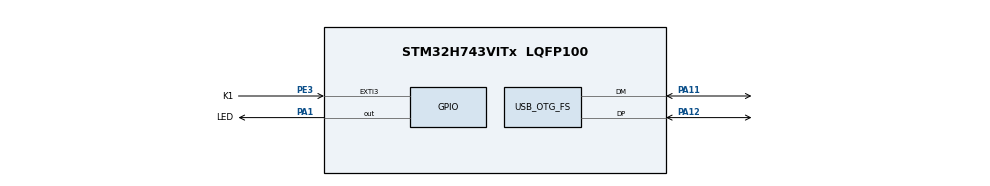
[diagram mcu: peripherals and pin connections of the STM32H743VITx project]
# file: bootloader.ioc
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CORTEX_M7.AccessPermission_S-Cortex_Memory_Protection_Unit_Region1_Settings_S=MPU_REGION_FULL_ACCESS
CORTEX_M7.BaseAddress_S-Cortex_Memory_Protection_Unit_Region1_Settings_S=0x20000000
CORTEX_M7.CPU_DCache=Enabled
CORTEX_M7.CPU_ICache=Enabled
CORTEX_M7.Enable_S-Cortex_Memory_Protection_Unit_Region1_Settings_S=MPU_REGION_ENABLE
CORTEX_M7.IsBufferable_S-Cortex_Memory_Protection_Unit_Region1_Settings_S=MPU_ACCESS_BUFFERABLE
CORTEX_M7.IsCacheable_S-Cortex_Memory_Protection_Unit_Region1_Settings_S=MPU_ACCESS_CACHEABLE
CORTEX_M7.Size_S-Cortex_Memory_Protection_Unit_Region1_Settings_S=MPU_REGION_SIZE_128KB
CORTEX_M7.default_mode_Activation=1
FREERTOS.Events01=defaultTaskEvent,Static,defaultTaskEventControlBlock
FREERTOS.HEAP_NUMBER=4
FREERTOS.Tasks01=defaultTask,24,4096,StartDefaultTask,As weak,NULL,Dynamic,NULL,NULL
FREERTOS.Timers01=usbTimer,usbTimerCallback,osTimerOnce,As external,NULL,Dynamic,NULL;lwipTimer,lwipTimerCallback,osTimerPeriodic,As external,NULL,Dynamic,NULL
FREERTOS.configCHECK_FOR_STACK_OVERFLOW=2
FREERTOS.configENABLE_FPU=1
FREERTOS.configMINIMAL_STACK_SIZE=256
FREERTOS.configTIMER_TASK_STACK_DEPTH=2048
FREERTOS.configTOTAL_HEAP_SIZE=0x10000
FREERTOS.configUSE_NEWLIB_REENTRANT=1
Mcu.Family=STM32H7
Mcu.Name=STM32H743VITx
Mcu.Package=LQFP100
NVIC.EXTI3_IRQn=true\:15\:0\:true\:false\:true\:true\:true\:true\:true
NVIC.FLASH_IRQn=true\:15\:0\:true\:false\:true\:true\:true\:true\:true
NVIC.OTG_FS_IRQn=true\:15\:0\:true\:false\:true\:true\:true\:true\:true
NVIC.PriorityGroup=NVIC_PRIORITYGROUP_4
NVIC.TIM6_DAC_IRQn=true\:15\:0\:false\:false\:true\:false\:false\:true\:true
NVIC.TimeBase=TIM6_DAC_IRQn
NVIC.TimeBaseIP=TIM6
PA1.GPIO_Label=LED
PA1.GPIO_ModeDefaultOutputPP=GPIO_MODE_OUTPUT_OD
PA1.GPIO_PuPd=GPIO_PULLUP
PA1.Signal=GPIO_Output
PA11.Mode=Device_Only
PA11.Signal=USB_OTG_FS_DM
PA12.Mode=Device_Only
PA12.Signal=USB_OTG_FS_DP
PA13\ (JTMS/SWDIO).Mode=Serial_Wire
PA13\ (JTMS/SWDIO).Signal=DEBUG_JTMS-SWDIO
PA14\ (JTCK/SWCLK).Mode=Serial_Wire
PA14\ (JTCK/SWCLK).Signal=DEBUG_JTCK-SWCLK
PE3.GPIO_Label=K1
PE3.GPIO_ModeDefaultEXTI=GPIO_MODE_IT_FALLING
PE3.GPIO_PuPd=GPIO_PULLUP
PE3.Signal=GPXTI3
PH0-OSC_IN\ (PH0).Mode=HSE-External-Oscillator
PH0-OSC_IN\ (PH0).Signal=RCC_OSC_IN
PH1-OSC_OUT\ (PH1).Mode=HSE-External-Oscillator
PH1-OSC_OUT\ (PH1).Signal=RCC_OSC_OUT
ProjectManager.HeapSize=0x200
ProjectManager.StackSize=0x400
ProjectManager.TargetToolchain=CMake
RCC.ADCFreq_Value=50390625
RCC.APB1Freq_Value=100000000
RCC.APB2Freq_Value=100000000
RCC.APB3Freq_Value=100000000
RCC.APB4Freq_Value=100000000
RCC.CortexFreq_Value=100000000
RCC.DIVM1=2
RCC.DIVN1=16
RCC.EnbaleCSS=true
RCC.HCLKFreq_Value=100000000
RCC.PLL2FRACN=0
RCC.PLL3FRACN=0
RCC.PLLFRACN=0
RCC.PLLSourceVirtual=RCC_PLLSOURCE_HSE
RCC.SYSCLKFreq_VALUE=100000000
RCC.SYSCLKSource=RCC_SYSCLKSOURCE_PLLCLK
RCC.USBCLockSelection=RCC_USBCLKSOURCE_HSI48
RCC.USBFreq_Value=48000000
USB_OTG_FS.VirtualMode=Device_Only
VP_FREERTOS_VS_CMSIS_V2.Mode=CMSIS_V2
VP_MEMORYMAP_VS_MEMORYMAP.Mode=CurAppReg
VP_SYS_VS_tim6.Mode=TIM6
board=custom

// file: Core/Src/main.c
/* USER CODE BEGIN Header */
/**
  ******************************************************************************
  * @file           : main.c
  * @brief          : Main program body
  ******************************************************************************
  * @attention
  *
  * Copyright (c) 2026 STMicroelectronics.
  * All rights reserved.
  *
  * This software is licensed under terms that can be found in the LICENSE file
  * in the root directory of this software component.
  * If no LICENSE file comes with this software, it is provided AS-IS.
  *
  ******************************************************************************
  */
/* USER CODE END Header */
#include "main.h"
#include "FreeRTOS.h"
#include "cmsis_os2.h"

/* USER CODE BEGIN Includes */
#include "bootloader-common.h"
/* USER CODE END Includes */

typedef StaticEventGroup_t osStaticEventGroupDef_t;

PCD_HandleTypeDef hpcd_USB_OTG_FS;

/* Definitions for defaultTask */
osThreadId_t defaultTaskHandle;
const osThreadAttr_t defaultTask_attributes = {
  .name = "defaultTask",
  .stack_size = 4096 * 4,
  .priority = (osPriority_t) osPriorityNormal,
};
/* Definitions for usbTimer */
osTimerId_t usbTimerHandle;
const osTimerAttr_t usbTimer_attributes = {
  .name = "usbTimer"
};
/* Definitions for lwipTimer */
osTimerId_t lwipTimerHandle;
const osTimerAttr_t lwipTimer_attributes = {
  .name = "lwipTimer"
};
/* Definitions for defaultTaskEvent */
osEventFlagsId_t defaultTaskEventHandle;
osStaticEventGroupDef_t defaultTaskEventControlBlock;
const osEventFlagsAttr_t defaultTaskEvent_attributes = {
  .name = "defaultTaskEvent",
  .cb_mem = &defaultTaskEventControlBlock,
  .cb_size = sizeof(defaultTaskEventControlBlock),
};

void SystemClock_Config(void);
static void MPU_Config(void);
static void MX_GPIO_Init(void);
static void MX_USB_OTG_FS_PCD_Init(void);
void StartDefaultTask(void *argument);
extern void usbTimerCallback(void *argument);
extern void lwipTimerCallback(void *argument);

int main(void)
{

  /* MPU Configuration--------------------------------------------------------*/
  MPU_Config();

  /* Enable the CPU Cache */

  /* Enable I-Cache---------------------------------------------------------*/
  SCB_EnableICache();

  /* Enable D-Cache---------------------------------------------------------*/
  SCB_EnableDCache();

  /* MCU Configuration--------------------------------------------------------*/

  /* Reset of all peripherals, Initializes the Flash interface and the Systick. */
  HAL_Init();

  /* USER CODE BEGIN Init */
  after_jump_to_bootloader();
  /* USER CODE END Init */

  /* Configure the system clock */
  SystemClock_Config();

  /* Initialize all configured peripherals */
  MX_GPIO_Init();
  MX_USB_OTG_FS_PCD_Init();

  /* Init scheduler */
  osKernelInitialize();

  /* Create the timer(s) */
  /* creation of usbTimer */
  usbTimerHandle = osTimerNew(usbTimerCallback, osTimerOnce, NULL, &usbTimer_attributes);

  /* creation of lwipTimer */
  lwipTimerHandle = osTimerNew(lwipTimerCallback, osTimerPeriodic, NULL, &lwipTimer_attributes);

  /* Create the thread(s) */
  /* creation of defaultTask */
  defaultTaskHandle = osThreadNew(StartDefaultTask, NULL, &defaultTask_attributes);

  /* Create the event(s) */
  /* creation of defaultTaskEvent */
  defaultTaskEventHandle = osEventFlagsNew(&defaultTaskEvent_attributes);

  /* Start scheduler */
  osKernelStart();

  /* We should never get here as control is now taken by the scheduler */

  /* Infinite loop */
  while (1)
  {

  }
}

void SystemClock_Config(void)
{
  RCC_OscInitTypeDef RCC_OscInitStruct = {0};
  RCC_ClkInitTypeDef RCC_ClkInitStruct = {0};

  /** Supply configuration update enable
  */
  HAL_PWREx_ConfigSupply(PWR_LDO_SUPPLY);

  /** Configure the main internal regulator output voltage
  */
  __HAL_PWR_VOLTAGESCALING_CONFIG(PWR_REGULATOR_VOLTAGE_SCALE3);

  while(!__HAL_PWR_GET_FLAG(PWR_FLAG_VOSRDY)) {}

  /** Initializes the RCC Oscillators according to the specified parameters
  * in the RCC_OscInitTypeDef structure.
  */
  RCC_OscInitStruct.OscillatorType = RCC_OSCILLATORTYPE_HSI48|RCC_OSCILLATORTYPE_HSE;
  RCC_OscInitStruct.HSEState = RCC_HSE_ON;
  RCC_OscInitStruct.HSI48State = RCC_HSI48_ON;
  RCC_OscInitStruct.PLL.PLLState = RCC_PLL_ON;
  RCC_OscInitStruct.PLL.PLLSource = RCC_PLLSOURCE_HSE;
  RCC_OscInitStruct.PLL.PLLM = 2;
  RCC_OscInitStruct.PLL.PLLN = 16;
  RCC_OscInitStruct.PLL.PLLP = 2;
  RCC_OscInitStruct.PLL.PLLQ = 2;
  RCC_OscInitStruct.PLL.PLLR = 2;
  RCC_OscInitStruct.PLL.PLLRGE = RCC_PLL1VCIRANGE_3;
  RCC_OscInitStruct.PLL.PLLVCOSEL = RCC_PLL1VCOWIDE;
  RCC_OscInitStruct.PLL.PLLFRACN = 0;
  if (HAL_RCC_OscConfig(&RCC_OscInitStruct) != HAL_OK)
  {
    Error_Handler();
  }

  /** Initializes the CPU, AHB and APB buses clocks
  */
  RCC_ClkInitStruct.ClockType = RCC_CLOCKTYPE_HCLK|RCC_CLOCKTYPE_SYSCLK
                              |RCC_CLOCKTYPE_PCLK1|RCC_CLOCKTYPE_PCLK2
                              |RCC_CLOCKTYPE_D3PCLK1|RCC_CLOCKTYPE_D1PCLK1;
  RCC_ClkInitStruct.SYSCLKSource = RCC_SYSCLKSOURCE_PLLCLK;
  RCC_ClkInitStruct.SYSCLKDivider = RCC_SYSCLK_DIV1;
  RCC_ClkInitStruct.AHBCLKDivider = RCC_HCLK_DIV1;
  RCC_ClkInitStruct.APB3CLKDivider = RCC_APB3_DIV1;
  RCC_ClkInitStruct.APB1CLKDivider = RCC_APB1_DIV1;
  RCC_ClkInitStruct.APB2CLKDivider = RCC_APB2_DIV1;
  RCC_ClkInitStruct.APB4CLKDivider = RCC_APB4_DIV1;

  if (HAL_RCC_ClockConfig(&RCC_ClkInitStruct, FLASH_LATENCY_2) != HAL_OK)
  {
    Error_Handler();
  }

  /** Enables the Clock Security System
  */
  HAL_RCC_EnableCSS();
}

static void MX_USB_OTG_FS_PCD_Init(void)
{

  hpcd_USB_OTG_FS.Instance = USB_OTG_FS;
  hpcd_USB_OTG_FS.Init.dev_endpoints = 9;
  hpcd_USB_OTG_FS.Init.speed = PCD_SPEED_FULL;
  hpcd_USB_OTG_FS.Init.dma_enable = DISABLE;
  hpcd_USB_OTG_FS.Init.phy_itface = PCD_PHY_EMBEDDED;
  hpcd_USB_OTG_FS.Init.Sof_enable = DISABLE;
  hpcd_USB_OTG_FS.Init.low_power_enable = DISABLE;
  hpcd_USB_OTG_FS.Init.lpm_enable = DISABLE;
  hpcd_USB_OTG_FS.Init.battery_charging_enable = DISABLE;
  hpcd_USB_OTG_FS.Init.vbus_sensing_enable = DISABLE;
  hpcd_USB_OTG_FS.Init.use_dedicated_ep1 = DISABLE;
  if (HAL_PCD_Init(&hpcd_USB_OTG_FS) != HAL_OK)
  {
    Error_Handler();
  }

}

static void MX_GPIO_Init(void)
{
  GPIO_InitTypeDef GPIO_InitStruct = {0};

  /* GPIO Ports Clock Enable */
  __HAL_RCC_GPIOE_CLK_ENABLE();
  __HAL_RCC_GPIOH_CLK_ENABLE();
  __HAL_RCC_GPIOA_CLK_ENABLE();

  /*Configure GPIO pin Output Level */
  HAL_GPIO_WritePin(LED_GPIO_Port, LED_Pin, GPIO_PIN_RESET);

  /*Configure GPIO pin : K1_Pin */
  GPIO_InitStruct.Pin = K1_Pin;
  GPIO_InitStruct.Mode = GPIO_MODE_IT_FALLING;
  GPIO_InitStruct.Pull = GPIO_PULLUP;
  HAL_GPIO_Init(K1_GPIO_Port, &GPIO_InitStruct);

  /*Configure GPIO pin : LED_Pin */
  GPIO_InitStruct.Pin = LED_Pin;
  GPIO_InitStruct.Mode = GPIO_MODE_OUTPUT_OD;
  GPIO_InitStruct.Pull = GPIO_PULLUP;
  GPIO_InitStruct.Speed = GPIO_SPEED_FREQ_LOW;
  HAL_GPIO_Init(LED_GPIO_Port, &GPIO_InitStruct);

  /*AnalogSwitch Config */
  HAL_SYSCFG_AnalogSwitchConfig(SYSCFG_SWITCH_PA1, SYSCFG_SWITCH_PA1_CLOSE);

  /* EXTI interrupt init*/
  HAL_NVIC_SetPriority(K1_EXTI_IRQn, 15, 0);
  HAL_NVIC_EnableIRQ(K1_EXTI_IRQn);

}

__weak void StartDefaultTask(void *argument)
{
  for(;;)
  {
    osDelay(1);
  }
}

 /* MPU Configuration */

void MPU_Config(void)
{
  MPU_Region_InitTypeDef MPU_InitStruct = {0};

  /* Disables the MPU */
  HAL_MPU_Disable();

  /** Initializes and configures the Region and the memory to be protected
  */
  MPU_InitStruct.Enable = MPU_REGION_ENABLE;
  MPU_InitStruct.Number = MPU_REGION_NUMBER0;
  MPU_InitStruct.BaseAddress = 0x0;
  MPU_InitStruct.Size = MPU_REGION_SIZE_4GB;
  MPU_InitStruct.SubRegionDisable = 0x87;
  MPU_InitStruct.TypeExtField = MPU_TEX_LEVEL0;
  MPU_InitStruct.AccessPermission = MPU_REGION_NO_ACCESS;
  MPU_InitStruct.DisableExec = MPU_INSTRUCTION_ACCESS_DISABLE;
  MPU_InitStruct.IsShareable = MPU_ACCESS_SHAREABLE;
  MPU_InitStruct.IsCacheable = MPU_ACCESS_NOT_CACHEABLE;
  MPU_InitStruct.IsBufferable = MPU_ACCESS_NOT_BUFFERABLE;

  HAL_MPU_ConfigRegion(&MPU_InitStruct);

  /** Initializes and configures the Region and the memory to be protected
  */
  MPU_InitStruct.Number = MPU_REGION_NUMBER1;
  MPU_InitStruct.BaseAddress = 0x20000000;
  MPU_InitStruct.Size = MPU_REGION_SIZE_128KB;
  MPU_InitStruct.SubRegionDisable = 0x0;
  MPU_InitStruct.AccessPermission = MPU_REGION_FULL_ACCESS;
  MPU_InitStruct.DisableExec = MPU_INSTRUCTION_ACCESS_ENABLE;
  MPU_InitStruct.IsShareable = MPU_ACCESS_NOT_SHAREABLE;
  MPU_InitStruct.IsCacheable = MPU_ACCESS_CACHEABLE;
  MPU_InitStruct.IsBufferable = MPU_ACCESS_BUFFERABLE;

  HAL_MPU_ConfigRegion(&MPU_InitStruct);
  /* Enables the MPU */
  HAL_MPU_Enable(MPU_PRIVILEGED_DEFAULT);

}

void HAL_TIM_PeriodElapsedCallback(TIM_HandleTypeDef *htim)
{
  if (htim->Instance == TIM6)
  {
    HAL_IncTick();
  }
}

void Error_Handler(void)
{
  __disable_irq();
  while (1)
  {
  }
}
